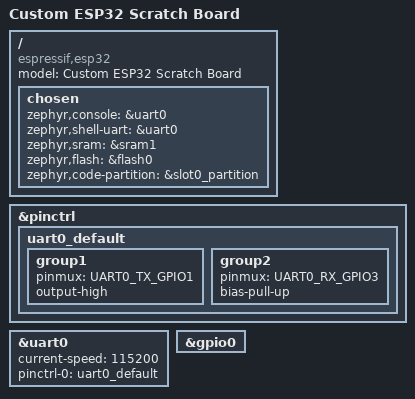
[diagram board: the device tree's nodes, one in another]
/dts-v1/;

#include <espressif/esp32/esp32_wrover_e_n4r8.dtsi>
#include <zephyr/dt-bindings/pinctrl/esp-pinctrl-common.h>
#include <dt-bindings/pinctrl/esp32-pinctrl.h>
#include <zephyr/dt-bindings/pinctrl/esp32-gpio-sigmap.h>
#include <espressif/partitions_0x1000_amp.dtsi>

/ {
    model = "Custom ESP32 Scratch Board";
    compatible = "espressif,esp32";

    chosen {
        zephyr,console = &uart0;
        zephyr,shell-uart = &uart0;
        zephyr,sram = &sram1;
        zephyr,flash = &flash0;
        zephyr,code-partition = &slot0_partition;
    };
};

&pinctrl {
    uart0_default: uart0_default {
        group1 {
            pinmux = <UART0_TX_GPIO1>;
            output-high;
        };
        group2 {
            pinmux = <UART0_RX_GPIO3>;
            bias-pull-up;
        };
    };
};

&uart0 {
    status = "okay";
    current-speed = <115200>;
    pinctrl-0 = <&uart0_default>;
    pinctrl-names = "default";
};

&gpio0 {
    status = "okay";
};
